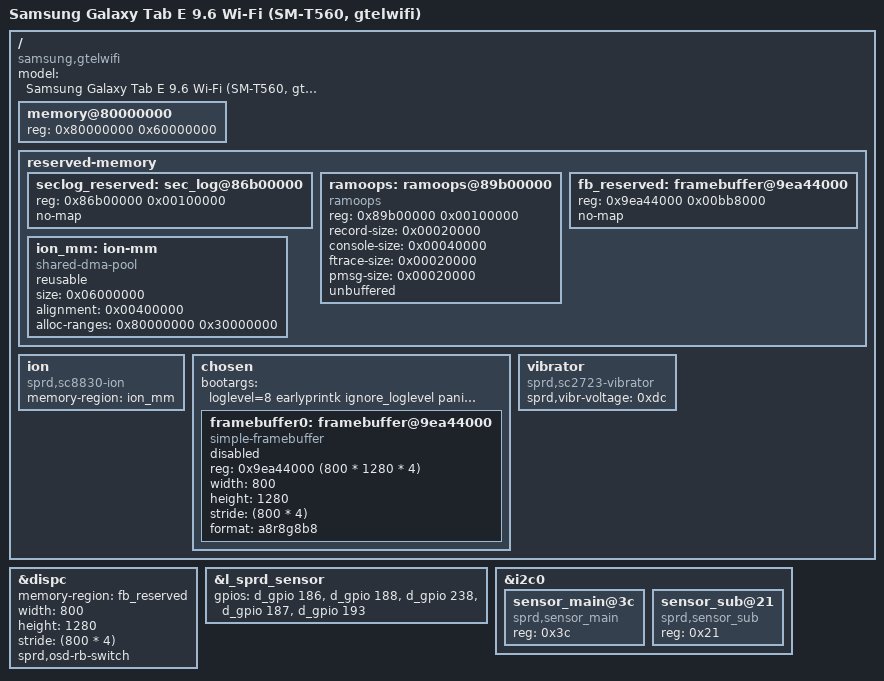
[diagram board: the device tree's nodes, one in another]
/dts-v1/;

/*
 * Samsung Galaxy Tab E 9.6 Wi-Fi (SM-T560 / gtelwifi) Device Tree
 *
 * Includes full Spreadtrum SC7730SE SoC peripherals, clocks, SC2723 PMIC
 * regulators, SDHCI eMMC/SD/Wi-Fi, Zinitix ZT7554 touchscreen, RT8555
 * backlight, keypad, simplefb, ramoops, and Samsung sec_log (/proc/last_kmsg).
 *
 * Licensed under the GPL-2.
 */

#include "sc7730se.dtsi"

/ {
	model = "Samsung Galaxy Tab E 9.6 Wi-Fi (SM-T560, gtelwifi)";
	compatible = "samsung,gtelwifi", "samsung,gtel3g", "sprd,sc7730se", "sprd,sc8830", "sprd,sp8830";

	memory@80000000 {
		device_type = "memory";
		reg = <0x80000000 0x60000000>;
	};

	reserved-memory {
		#address-cells = <1>;
		#size-cells = <1>;
		ranges;

		/* Samsung S-Boot & TWRP /proc/last_kmsg buffer (sec_log=0xffe00@0x86b00000) */
		seclog_reserved: sec_log@86b00000 {
			reg = <0x86b00000 0x00100000>;
			no-map;
		};

		/* Linux pstore/ramoops persistent crash log at 0x89b00000 */
		ramoops: ramoops@89b00000 {
			compatible = "ramoops";
			reg = <0x89b00000 0x00100000>;
			record-size = <0x00020000>;
			console-size = <0x00040000>;
			ftrace-size = <0x00020000>;
			pmsg-size = <0x00020000>;
			unbuffered;
		};

		/*
		 * S-Boot pre-initialized 800x1280x32bpp display framebuffer,
		 * three pages for page flipping (the 3.10 kernel's sprd,fb_mem)
		 */
		fb_reserved: framebuffer@9ea44000 {
			reg = <0x9ea44000 0x00bb8000>;
			no-map;
		};

		/*
		 * ION heap 2 (video/camera): the VSP and JPEG codecs have no
		 * IOMMU.  Movable pages use the pool while no codec does; it
		 * stays in lowmem (below 0xb0000000) so it is linearly mapped.
		 */
		ion_mm: ion-mm {
			compatible = "shared-dma-pool";
			reusable;
			size = <0x06000000>;
			alignment = <0x00400000>;
			alloc-ranges = <0x80000000 0x30000000>;
		};
	};

	ion {
		compatible = "sprd,sc8830-ion";
		memory-region = <&ion_mm>;
	};

	chosen {
		bootargs = "loglevel=8 earlyprintk ignore_loglevel panic=10 root=/dev/mmcblk0p20 rw rootwait init=/init androidboot.hardware=sc8830 androidboot.selinux=permissive enforcing=0";
		#address-cells = <1>;
		#size-cells = <1>;
		ranges;

		framebuffer0: framebuffer@9ea44000 {
			compatible = "simple-framebuffer";
			reg = <0x9ea44000 (800 * 1280 * 4)>;
			width = <800>;
			height = <1280>;
			stride = <(800 * 4)>;
			format = "a8r8g8b8";
			/* superseded by the DISPC framebuffer driver (&dispc) */
			status = "disabled";
		};
	};
};

&dispc {
	memory-region = <&fb_reserved>;
	width = <800>;
	height = <1280>;
	stride = <(800 * 4)>;
	/* Android's gralloc renders RGBA; S-Boot scans out BGRA */
	sprd,osd-rb-switch;
	status = "okay";
};

/ {
	vibrator {
		compatible = "sprd,sc2723-vibrator";
		sprd,vibr-voltage = <0xdc>;	/* 3.4 V */
	};
};

&l_sprd_sensor {
	gpios = <&d_gpio 186 0           /*main reset*/
		 &d_gpio 188 0           /*main power down*/
		 &d_gpio 238 0           /*sub reset*/
		 &d_gpio 187 0           /*sub power down*/
		 &d_gpio 193 0>;         /*main dvdd en*/
};

&i2c0 {
	sensor_main@3c {
		compatible = "sprd,sensor_main";
		reg = <0x3c>;
	};

	sensor_sub@21 {
		compatible = "sprd,sensor_sub";
		reg = <0x21>;
	};
};
